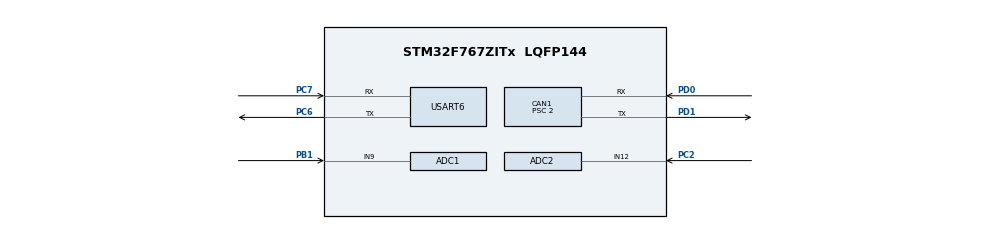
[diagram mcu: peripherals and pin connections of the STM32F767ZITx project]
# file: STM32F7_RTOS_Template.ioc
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ADC1.Channel-1\#ChannelRegularConversion=ADC_CHANNEL_9
ADC1.NbrOfConversionFlag=1
ADC1.Rank-1\#ChannelRegularConversion=1
ADC1.SamplingTime-1\#ChannelRegularConversion=ADC_SAMPLETIME_3CYCLES
ADC1.master=1
ADC2.Channel-0\#ChannelRegularConversion=ADC_CHANNEL_12
ADC2.NbrOfConversionFlag=1
ADC2.Rank-0\#ChannelRegularConversion=1
ADC2.SamplingTime-0\#ChannelRegularConversion=ADC_SAMPLETIME_3CYCLES
CAN1.BS1=CAN_BS1_5TQ
CAN1.BS2=CAN_BS2_2TQ
CAN1.CalculateBaudRate=1000000
CAN1.CalculateTimeBit=1000
CAN1.CalculateTimeQuantum=125.0
CAN1.Prescaler=2
CORTEX_M7.default_mode_Activation=1
Dma.Request0=USART6_RX
Dma.USART6_RX.0.Direction=DMA_PERIPH_TO_MEMORY
Dma.USART6_RX.0.FIFOMode=DMA_FIFOMODE_DISABLE
Dma.USART6_RX.0.Instance=DMA2_Stream1
Dma.USART6_RX.0.MemDataAlignment=DMA_MDATAALIGN_BYTE
Dma.USART6_RX.0.MemInc=DMA_MINC_ENABLE
Dma.USART6_RX.0.Mode=DMA_NORMAL
Dma.USART6_RX.0.PeriphDataAlignment=DMA_PDATAALIGN_BYTE
Dma.USART6_RX.0.PeriphInc=DMA_PINC_DISABLE
Dma.USART6_RX.0.Priority=DMA_PRIORITY_LOW
FREERTOS.Tasks01=controlTask,24,256,StartControlTask,Default,NULL,Dynamic,NULL,NULL;feedbackTask,8,256,StartFeedbackTask,Default,NULL,Dynamic,NULL,NULL;readADCTask,16,256,StartReadADCTask,Default,NULL,Dynamic,NULL,NULL
FREERTOS.configUSE_NEWLIB_REENTRANT=1
Mcu.Family=STM32F7
Mcu.Name=STM32F767ZITx
Mcu.Package=LQFP144
NVIC.DMA2_Stream1_IRQn=true\:5\:0\:false\:false\:true\:true\:false\:true\:true
NVIC.PriorityGroup=NVIC_PRIORITYGROUP_4
NVIC.TIM6_DAC_IRQn=true\:15\:0\:false\:false\:true\:false\:false\:true\:true
NVIC.TimeBase=TIM6_DAC_IRQn
NVIC.TimeBaseIP=TIM6
PB1.Signal=ADCx_IN9
PC2.Signal=ADCx_IN12
PC6.Mode=Asynchronous
PC6.Signal=USART6_TX
PC7.Mode=Asynchronous
PC7.Signal=USART6_RX
PD0.Mode=CAN_Activate
PD0.Signal=CAN1_RX
PD1.Mode=CAN_Activate
PD1.Signal=CAN1_TX
ProjectManager.HeapSize=0x200
ProjectManager.StackSize=0x400
ProjectManager.TargetToolchain=STM32CubeIDE
RCC.HSE_VALUE=25000000
RCC.HSI_VALUE=16000000
RCC.LSE_VALUE=32768
RCC.USBFreq_Value=96000000
RCC.VCOOutputFreq_Value=192000000
SH.ADCx_IN12.0=ADC2_IN12,IN12
SH.ADCx_IN9.0=ADC1_IN9,IN9
USART6.VirtualMode-Asynchronous=VM_ASYNC
VP_FREERTOS_VS_CMSIS_V2.Mode=CMSIS_V2
VP_SYS_VS_tim6.Mode=TIM6
board=custom

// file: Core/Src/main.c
/* USER CODE BEGIN Header */
/**
  ******************************************************************************
  * @file           : main.c
  * @brief          : Main program body
  ******************************************************************************
  * @attention
  *
  * Copyright (c) 2025 STMicroelectronics.
  * All rights reserved.
  *
  * This software is licensed under terms that can be found in the LICENSE file
  * in the root directory of this software component.
  * If no LICENSE file comes with this software, it is provided AS-IS.
  *
  ******************************************************************************
  */
/* USER CODE END Header */
#include "main.h"
#include "cmsis_os.h"
#include "adc.h"
#include "can.h"
#include "dma.h"
#include "usart.h"
#include "gpio.h"

void SystemClock_Config(void);
static void MPU_Config(void);
void MX_FREERTOS_Init(void);

int main(void)
{

  /* MPU Configuration--------------------------------------------------------*/
  MPU_Config();

  /* MCU Configuration--------------------------------------------------------*/

  /* Reset of all peripherals, Initializes the Flash interface and the Systick. */
  HAL_Init();

  /* Configure the system clock */
  SystemClock_Config();

  /* Initialize all configured peripherals */
  MX_GPIO_Init();
  MX_DMA_Init();
  MX_CAN1_Init();
  MX_USART6_UART_Init();
  MX_ADC1_Init();
  MX_ADC2_Init();

  /* Init scheduler */
  osKernelInitialize();  /* Call init function for freertos objects (in cmsis_os2.c) */
  MX_FREERTOS_Init();

  /* Start scheduler */
  osKernelStart();

  /* We should never get here as control is now taken by the scheduler */

  /* Infinite loop */
  while (1)
  {

  }
}

void SystemClock_Config(void)
{
  RCC_OscInitTypeDef RCC_OscInitStruct = {0};
  RCC_ClkInitTypeDef RCC_ClkInitStruct = {0};

  /** Configure the main internal regulator output voltage
  */
  __HAL_RCC_PWR_CLK_ENABLE();
  __HAL_PWR_VOLTAGESCALING_CONFIG(PWR_REGULATOR_VOLTAGE_SCALE3);

  /** Initializes the RCC Oscillators according to the specified parameters
  * in the RCC_OscInitTypeDef structure.
  */
  RCC_OscInitStruct.OscillatorType = RCC_OSCILLATORTYPE_HSI;
  RCC_OscInitStruct.HSIState = RCC_HSI_ON;
  RCC_OscInitStruct.HSICalibrationValue = RCC_HSICALIBRATION_DEFAULT;
  RCC_OscInitStruct.PLL.PLLState = RCC_PLL_NONE;
  if (HAL_RCC_OscConfig(&RCC_OscInitStruct) != HAL_OK)
  {
    Error_Handler();
  }

  /** Initializes the CPU, AHB and APB buses clocks
  */
  RCC_ClkInitStruct.ClockType = RCC_CLOCKTYPE_HCLK|RCC_CLOCKTYPE_SYSCLK
                              |RCC_CLOCKTYPE_PCLK1|RCC_CLOCKTYPE_PCLK2;
  RCC_ClkInitStruct.SYSCLKSource = RCC_SYSCLKSOURCE_HSI;
  RCC_ClkInitStruct.AHBCLKDivider = RCC_SYSCLK_DIV1;
  RCC_ClkInitStruct.APB1CLKDivider = RCC_HCLK_DIV1;
  RCC_ClkInitStruct.APB2CLKDivider = RCC_HCLK_DIV1;

  if (HAL_RCC_ClockConfig(&RCC_ClkInitStruct, FLASH_LATENCY_0) != HAL_OK)
  {
    Error_Handler();
  }
}

 /* MPU Configuration */

void MPU_Config(void)
{
  MPU_Region_InitTypeDef MPU_InitStruct = {0};

  /* Disables the MPU */
  HAL_MPU_Disable();

  /** Initializes and configures the Region and the memory to be protected
  */
  MPU_InitStruct.Enable = MPU_REGION_ENABLE;
  MPU_InitStruct.Number = MPU_REGION_NUMBER0;
  MPU_InitStruct.BaseAddress = 0x0;
  MPU_InitStruct.Size = MPU_REGION_SIZE_4GB;
  MPU_InitStruct.SubRegionDisable = 0x87;
  MPU_InitStruct.TypeExtField = MPU_TEX_LEVEL0;
  MPU_InitStruct.AccessPermission = MPU_REGION_NO_ACCESS;
  MPU_InitStruct.DisableExec = MPU_INSTRUCTION_ACCESS_DISABLE;
  MPU_InitStruct.IsShareable = MPU_ACCESS_SHAREABLE;
  MPU_InitStruct.IsCacheable = MPU_ACCESS_NOT_CACHEABLE;
  MPU_InitStruct.IsBufferable = MPU_ACCESS_NOT_BUFFERABLE;

  HAL_MPU_ConfigRegion(&MPU_InitStruct);
  /* Enables the MPU */
  HAL_MPU_Enable(MPU_PRIVILEGED_DEFAULT);

}

void HAL_TIM_PeriodElapsedCallback(TIM_HandleTypeDef *htim)
{
  if (htim->Instance == TIM6)
  {
    HAL_IncTick();
  }
}

void Error_Handler(void)
{
  __disable_irq();
  while (1)
  {
  }
}

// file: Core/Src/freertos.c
/* USER CODE BEGIN Header */
/**
  ******************************************************************************
  * File Name          : freertos.c
  * Description        : Code for freertos applications
  ******************************************************************************
  * @attention
  *
  * Copyright (c) 2025 STMicroelectronics.
  * All rights reserved.
  *
  * This software is licensed under terms that can be found in the LICENSE file
  * in the root directory of this software component.
  * If no LICENSE file comes with this software, it is provided AS-IS.
  *
  ******************************************************************************
  */
/* USER CODE END Header */

#include "FreeRTOS.h"
#include "task.h"
#include "main.h"
#include "cmsis_os.h"

/* USER CODE BEGIN Includes */
#include "usart.h"
#include "can.h"
/* USER CODE END Includes */

/* Definitions for controlTask */
osThreadId_t controlTaskHandle;
const osThreadAttr_t controlTask_attributes = {
  .name = "controlTask",
  .stack_size = 256 * 4,
  .priority = (osPriority_t) osPriorityNormal,
};
/* Definitions for feedbackTask */
osThreadId_t feedbackTaskHandle;
const osThreadAttr_t feedbackTask_attributes = {
  .name = "feedbackTask",
  .stack_size = 256 * 4,
  .priority = (osPriority_t) osPriorityLow,
};
/* Definitions for readADCTask */
osThreadId_t readADCTaskHandle;
const osThreadAttr_t readADCTask_attributes = {
  .name = "readADCTask",
  .stack_size = 256 * 4,
  .priority = (osPriority_t) osPriorityBelowNormal,
};

void StartControlTask(void *argument);
void StartFeedbackTask(void *argument);
void StartReadADCTask(void *argument);

void MX_FREERTOS_Init(void); /* (MISRA C 2004 rule 8.1) */

void MX_FREERTOS_Init(void) {

  /* Create the thread(s) */
  /* creation of controlTask */
  controlTaskHandle = osThreadNew(StartControlTask, NULL, &controlTask_attributes);

  /* creation of feedbackTask */
  feedbackTaskHandle = osThreadNew(StartFeedbackTask, NULL, &feedbackTask_attributes);

  /* creation of readADCTask */
  readADCTaskHandle = osThreadNew(StartReadADCTask, NULL, &readADCTask_attributes);

}

void StartControlTask(void *argument)
{
  /* USER CODE BEGIN StartControlTask */
	// todo: Implement directControl() from "control.c" here

  /* Infinite loop */
  for(;;)
  {
    osDelay(1);
  }
  /* USER CODE END StartControlTask */
}

void StartFeedbackTask(void *argument)
{
  /* USER CODE BEGIN StartFeedbackTask */
	// todo: implement writeToJetson() from "serial.c" here
  /* Infinite loop */
  for(;;)
  {
    osDelay(1);
  }
  /* USER CODE END StartFeedbackTask */
}

void StartReadADCTask(void *argument)
{
  /* USER CODE BEGIN StartReadADCTask */
	// todo: implement readPot() from "pot.c" here
  /* Infinite loop */
  for(;;)
  {
    osDelay(1);
  }
  /* USER CODE END StartReadADCTask */
}
